# STM32H757xx_CM4 register map
File version: 1.0
Registers are 32-bit, read-write, reset 0x0 unless marked. A register's access mark holds for its fields unless they carry their own. Offsets are from the block's base; [hi:lo] are bit positions; {n}, {i} and the like mark numbered series; 'fields as' and 'values as' point back to an identical list.

## RCC — Reset and Clock Control
Base 0x58024400
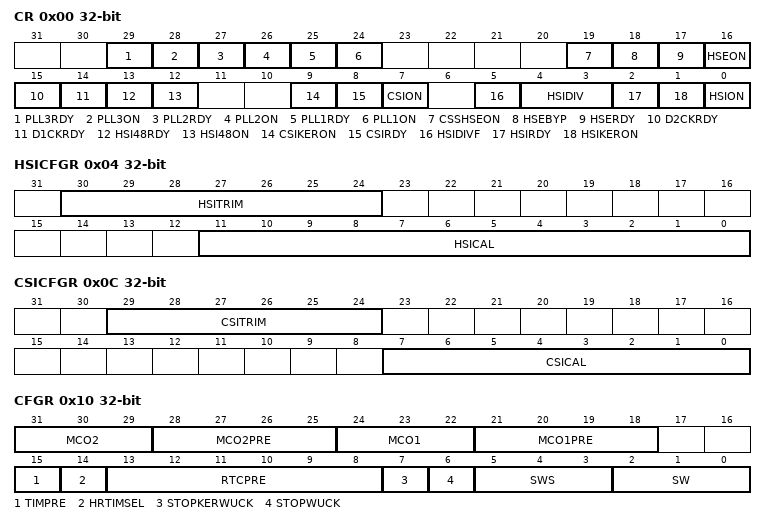
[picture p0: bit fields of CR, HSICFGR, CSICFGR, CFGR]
0x00 CR — RCC clock control register
  [29] PLL3RDY — System PLL3 clock ready
  [28] PLL3ON — System PLL3 clock enable
  [27] PLL2RDY — System PLL2 clock ready
  [26] PLL2ON — System PLL2 clock enable
  [25] PLL1RDY — System PLL1 clock ready
  [24] PLL1ON — System PLL1 clock enable
  [19] CSSHSEON — HSE Clock security System enable
  [18] HSEBYP — External High Speed clock Bypass
  [17] HSERDY — External High Speed clock ready
  [16] HSEON — External High Speed clock enable
  [15] D2CKRDY — D2 domain clocks ready flag
  [14] D1CKRDY — D1 domain clocks ready flag
  [13] HSI48RDY — HSI48 clock ready
  [12] HSI48ON — HSI48 clock enable clock enable
  [9] CSIKERON — Internal RC 4MHz oscillator clock enable for some IPs Kernel
  [8] CSIRDY — The Internal RC 4MHz oscillator clock ready
  [7] CSION — The Internal RC 4MHz oscillator clock enable
  [5] HSIDIVF — HSI Divider flag
  [4:3] HSIDIV — Internal High Speed clock divider selection
    0=DIV1; 1=DIV2; 2=DIV4; 3=DIV8
  [2] HSIRDY — Internal High Speed clock ready flag
  [1] HSIKERON — Internal High Speed clock enable for some IPs Kernel
  [0] HSION — Internal High Speed clock enable
0x04 HSICFGR — HSI Clock Calibration Register
  [30:24] HSITRIM — HSITRIM[6:0] bits
  [11:0] HSICAL — HSICAL[11:0] bits
0x08 CRRCR — Clock Recovery RC Register
  [9:0] HSI48CAL — HSI48CAL[9:0] bits
0x0C CSICFGR — CSI Clock Calibration Register
  [29:24] CSITRIM — CSITRIM[5:0] bits
  [7:0] CSICAL — CSICAL[7:0] bits
0x10 CFGR — RCC clock configuration register
  [31:29] MCO2
  [28:25] MCO2PRE
  [24:22] MCO1
  [21:18] MCO1PRE
  [15] TIMPRE
    0=TWICE; 1=FOUR_TIMES
  [14] HRTIMSEL
    0=TIM; 1=CPU
  [13:8] RTCPRE
    0=NOCLOCK; {v}=HSE_DIV_{v} (v=2..63)
  [7] STOPKERWUCK — Kernel Clock Selection after a Wake Up from STOP
    0=HSI; 1=CSI
  [6] STOPWUCK — Wake Up from stop and CSS backup clock selection
    0=HSI; 1=CSI
  [5:3] SWS — SWS[2:0] bits (System Clock Switch Status)
    0=HSI (HSI used as system clock); 1=CSI (CSI used as system clock); 2=HSE (HSE used as system clock); 3=PLL1 (PLL1 used as system clock)
  [2:0] SW — SW[2:0] bits (System clock Switch)
    0=HSI; 1=CSI; 2=HSE; 3=PLL1
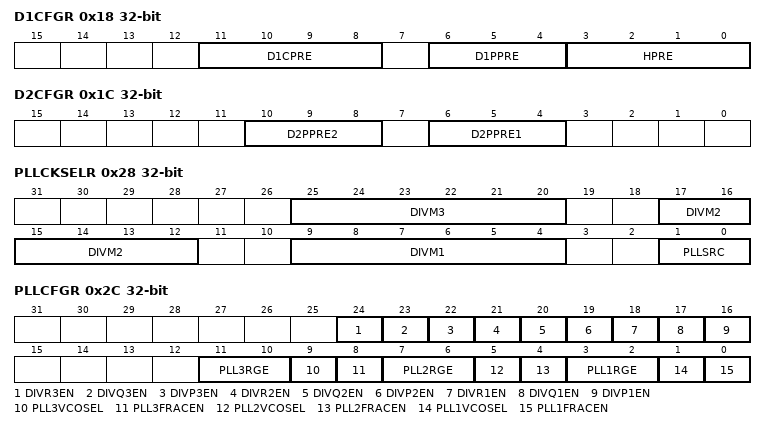
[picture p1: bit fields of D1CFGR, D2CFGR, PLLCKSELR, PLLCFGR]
0x18 D1CFGR — RCC Domain 1 configuration register
  [11:8] D1CPRE — D1CPRE[2:0] bits (Domain 1 Core prescaler)
  [6:4] D1PPRE — D1PRE[2:0] bits (APB3 prescaler)
  [3:0] HPRE — HPRE[3:0] bits (AHB3 prescaler)
0x1C D2CFGR — RCC Domain 2 configuration register
  [10:8] D2PPRE2 — D2PPRE2[2:0] bits (APB2 prescaler)
  [6:4] D2PPRE1 — D1PPRE1[2:0] bits (APB1 prescaler)
0x20 D3CFGR — RCC Domain 3 configuration register
  [6:4] D3PPRE — D3PPRE1[2:0] bits (APB4 prescaler)
0x28 PLLCKSELR — RCC PLLs Clock Source Selection Register
  [25:20] DIVM3
  [17:12] DIVM2
  [9:4] DIVM1
  [1:0] PLLSRC
    0=HSI; 1=CSI; 2=HSE; 3=NONE
0x2C PLLCFGR — RCC PLLs Configuration Register
  [24] DIVR3EN, [23] DIVQ3EN, [22] DIVP3EN, [21] DIVR2EN, [20] DIVQ2EN, [19] DIVP2EN, [18] DIVR1EN, [17] DIVQ1EN, [16] DIVP1EN, [11:10] PLL3RGE, [9] PLL3VCOSEL, [8] PLL3FRACEN, [7:6] PLL2RGE, [5] PLL2VCOSEL, [4] PLL2FRACEN, [3:2] PLL1RGE, [1] PLL1VCOSEL, [0] PLL1FRACEN
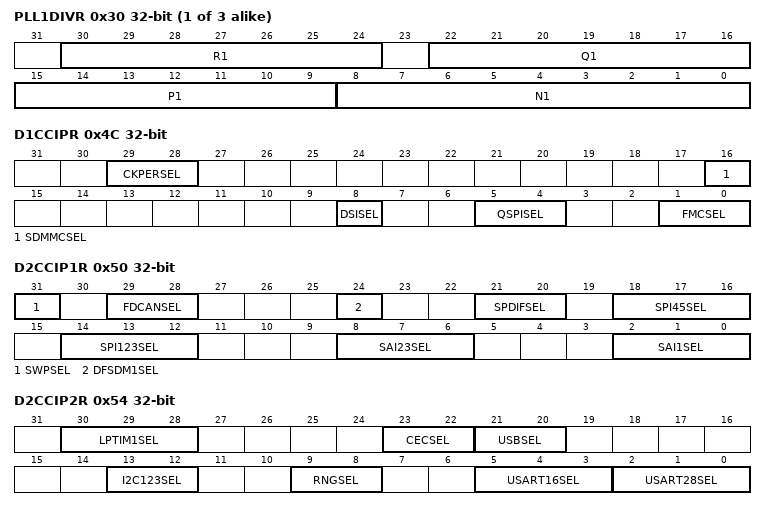
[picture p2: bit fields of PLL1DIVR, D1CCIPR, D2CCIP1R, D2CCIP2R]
{0x28+8i} PLL{i}DIVR (i=1..3) — RCC PLL{i} Dividers Configuration Register
  [30:24] R{i}, [22:16] Q{i}, [15:9] P{i}, [8:0] N{i}
{0x2C+8i} PLL{i}FRACR (i=1..3) — RCC PLL{i} Fractional Divider Configuration Register
  [15:3] FRACN{i}
0x4C D1CCIPR — RCC Domain 1 Kernel Clock Configuration Register
  [29:28] CKPERSEL
  [16] SDMMCSEL
  [8] DSISEL
    0=PHY; 1=PLL2Q
  [5:4] QSPISEL
    0=HCLK; 1=PLL1Q; 2=PLL2R; 3=CLKP
  [1:0] FMCSEL
0x50 D2CCIP1R — RCC Domain 2 Kernel Clock Configuration Register
  [31] SWPSEL, [29:28] FDCANSEL, [24] DFSDM1SEL, [21:20] SPDIFSEL, [18:16] SPI45SEL, [14:12] SPI123SEL, [8:6] SAI23SEL, [2:0] SAI1SEL
0x54 D2CCIP2R — RCC Domain 2 Kernel Clock Configuration Register
  [30:28] LPTIM1SEL, [23:22] CECSEL, [21:20] USBSEL, [13:12] I2C123SEL, [9:8] RNGSEL, [5:3] USART16SEL, [2:0] USART28SEL
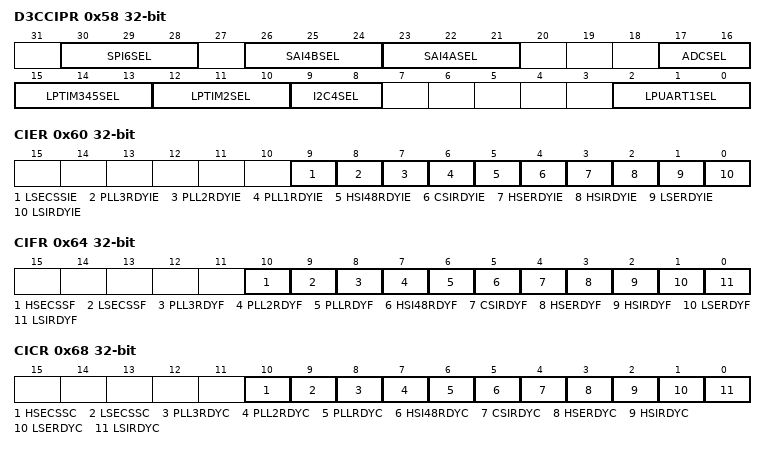
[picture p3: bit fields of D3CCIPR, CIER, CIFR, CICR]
0x58 D3CCIPR — RCC Domain 3 Kernel Clock Configuration Register
  [30:28] SPI6SEL, [26:24] SAI4BSEL, [23:21] SAI4ASEL, [17:16] ADCSEL, [15:13] LPTIM345SEL, [12:10] LPTIM2SEL, [9:8] I2C4SEL, [2:0] LPUART1SEL
0x60 CIER — RCC Clock Source Interrupt Enable Register
  [9] LSECSSIE, [8] PLL3RDYIE, [7] PLL2RDYIE, [6] PLL1RDYIE, [5] HSI48RDYIE, [4] CSIRDYIE, [3] HSERDYIE, [2] HSIRDYIE, [1] LSERDYIE, [0] LSIRDYIE
0x64 CIFR — RCC Clock Source Interrupt Flag Register
  [10] HSECSSF, [9] LSECSSF, [8] PLL3RDYF, [7] PLL2RDYF, [6] PLLRDYF, [5] HSI48RDYF, [4] CSIRDYF, [3] HSERDYF, [2] HSIRDYF, [1] LSERDYF, [0] LSIRDYF
0x68 CICR — RCC Clock Source Interrupt Clear Register
  [10] HSECSSC, [9] LSECSSC, [8] PLL3RDYC, [7] PLL2RDYC, [6] PLLRDYC, [5] HSI48RDYC, [4] CSIRDYC, [3] HSERDYC, [2] HSIRDYC, [1] LSERDYC, [0] LSIRDYC
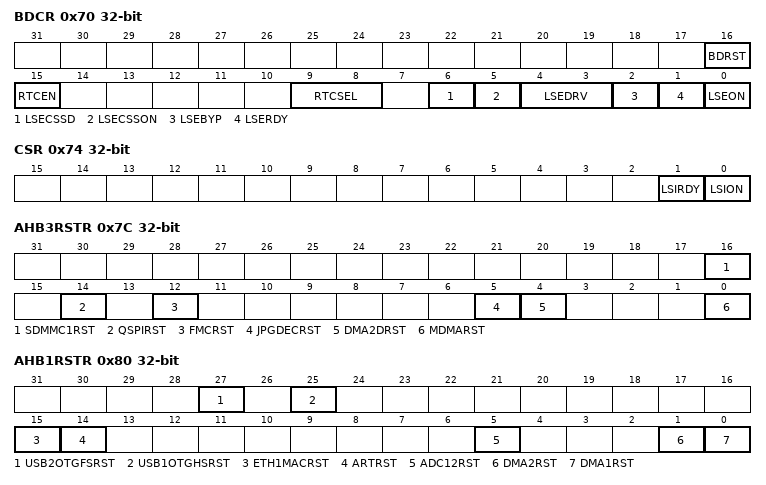
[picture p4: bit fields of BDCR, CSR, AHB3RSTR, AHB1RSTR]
0x70 BDCR — RCC Vswitch Backup Domain Control Register
  [16] BDRST
  [15] RTCEN
  [9:8] RTCSEL
    0=NONE; 1=LSE; 2=LSI; 3=HSE
  [6] LSECSSD
  [5] LSECSSON
  [4:3] LSEDRV
    0=LOW; 1=MEDIUMLOW; 2=MEDIUMHIGH; 3=HIGH
  [2] LSEBYP
  [1] LSERDY
  [0] LSEON
0x74 CSR — RCC clock control & status register
  [1] LSIRDY, [0] LSION
0x7C AHB3RSTR — RCC AHB3 peripheral reset register
  [16] SDMMC1RST, [14] QSPIRST, [12] FMCRST, [5] JPGDECRST, [4] DMA2DRST, [0] MDMARST
0x80 AHB1RSTR — RCC AHB1 peripheral reset register
  [27] USB2OTGFSRST, [25] USB1OTGHSRST, [15] ETH1MACRST, [14] ARTRST, [5] ADC12RST, [1] DMA2RST, [0] DMA1RST
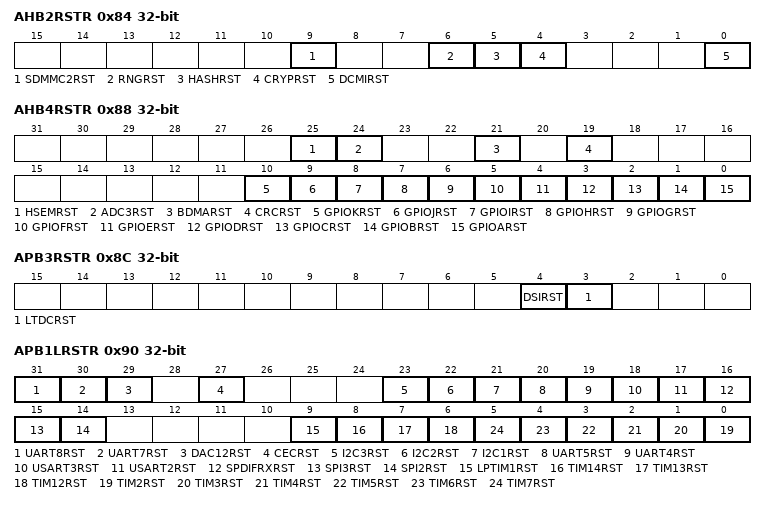
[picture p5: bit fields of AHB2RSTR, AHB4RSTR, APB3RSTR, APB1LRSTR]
0x84 AHB2RSTR — RCC AHB2 peripheral reset register
  [9] SDMMC2RST, [6] RNGRST, [5] HASHRST, [4] CRYPRST, [0] DCMIRST
0x88 AHB4RSTR — RCC AHB4 peripheral reset register
  [25] HSEMRST, [24] ADC3RST, [21] BDMARST, [19] CRCRST, [10] GPIOKRST, [9] GPIOJRST, [8] GPIOIRST, [7] GPIOHRST, [6] GPIOGRST, [5] GPIOFRST, [4] GPIOERST, [3] GPIODRST, [2] GPIOCRST, [1] GPIOBRST, [0] GPIOARST
0x8C APB3RSTR — RCC APB3 peripheral reset register
  [4] DSIRST, [3] LTDCRST
0x90 APB1LRSTR — RCC APB1 peripheral reset Low Word register
  [31] UART8RST, [30] UART7RST, [29] DAC12RST, [27] CECRST, [23] I2C3RST, [22] I2C2RST, [21] I2C1RST, [20] UART5RST, [19] UART4RST, [18] USART3RST, [17] USART2RST, [16] SPDIFRXRST, [15] SPI3RST, [14] SPI2RST, [9] LPTIM1RST, [8] TIM14RST, [7] TIM13RST, [6] TIM12RST, [n-2] TIM{n}RST (n=2..7)
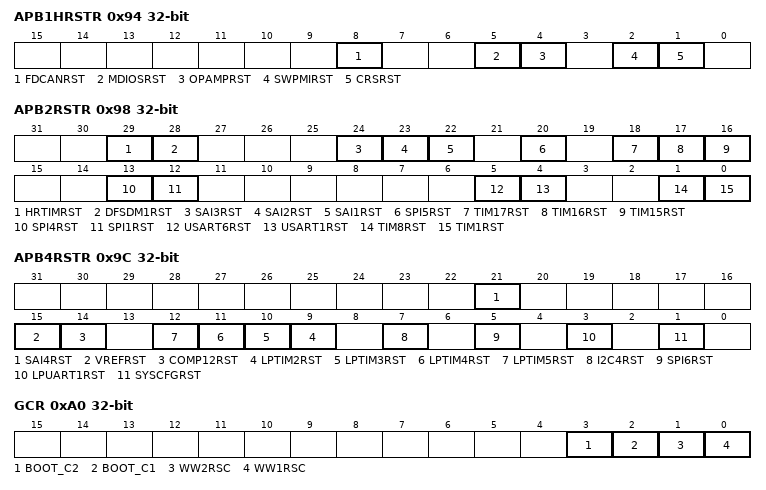
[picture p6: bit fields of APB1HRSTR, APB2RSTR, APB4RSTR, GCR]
0x94 APB1HRSTR — RCC APB1 peripheral reset High Word register
  [8] FDCANRST, [5] MDIOSRST, [4] OPAMPRST, [2] SWPMIRST, [1] CRSRST
0x98 APB2RSTR — RCC APB2 peripheral reset register
  [29] HRTIMRST, [28] DFSDM1RST, [24] SAI3RST, [23] SAI2RST, [22] SAI1RST, [20] SPI5RST, [18] TIM17RST, [17] TIM16RST, [16] TIM15RST, [13] SPI4RST, [12] SPI1RST, [5] USART6RST, [4] USART1RST, [1] TIM8RST, [0] TIM1RST
0x9C APB4RSTR — RCC APB4 peripheral reset register
  [21] SAI4RST, [15] VREFRST, [14] COMP12RST, [n+7] LPTIM{n}RST (n=2..5), [7] I2C4RST, [5] SPI6RST, [3] LPUART1RST, [1] SYSCFGRST
0xA0 GCR — RCC RCC Global Control Register
  [3] BOOT_C2, [2] BOOT_C1, [1] WW2RSC, [0] WW1RSC
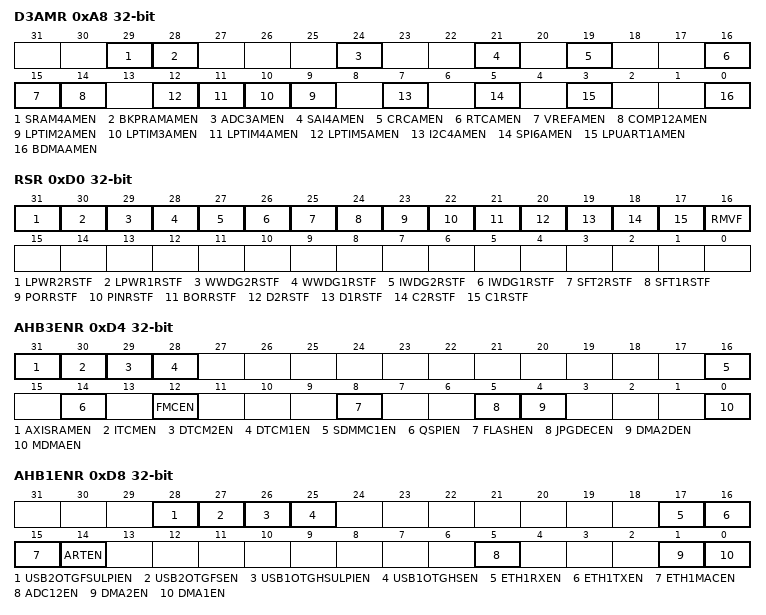
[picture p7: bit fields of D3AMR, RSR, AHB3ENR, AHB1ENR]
0xA8 D3AMR — RCC Domain 3 Autonomous Mode Register
  [29] SRAM4AMEN, [28] BKPRAMAMEN, [24] ADC3AMEN, [21] SAI4AMEN, [19] CRCAMEN, [16] RTCAMEN, [15] VREFAMEN, [14] COMP12AMEN, [n+7] LPTIM{n}AMEN (n=2..5), [7] I2C4AMEN, [5] SPI6AMEN, [3] LPUART1AMEN, [0] BDMAAMEN
0xD0 RSR — RCC Reset status register
  [31] LPWR2RSTF, [30] LPWR1RSTF, [29] WWDG2RSTF, [28] WWDG1RSTF, [27] IWDG2RSTF, [26] IWDG1RSTF, [25] SFT2RSTF, [24] SFT1RSTF, [23] PORRSTF, [22] PINRSTF, [21] BORRSTF, [20] D2RSTF, [19] D1RSTF, [18] C2RSTF, [17] C1RSTF, [16] RMVF
0xD4 AHB3ENR — RCC AHB3 peripheral clock register
  [31] AXISRAMEN, [30] ITCMEN, [29] DTCM2EN, [28] DTCM1EN, [16] SDMMC1EN, [14] QSPIEN, [12] FMCEN, [8] FLASHEN, [5] JPGDECEN, [4] DMA2DEN, [0] MDMAEN
0xD8 AHB1ENR — RCC AHB1 peripheral clock register
  [28] USB2OTGFSULPIEN, [27] USB2OTGFSEN, [26] USB1OTGHSULPIEN, [25] USB1OTGHSEN, [17] ETH1RXEN, [16] ETH1TXEN, [15] ETH1MACEN, [14] ARTEN, [5] ADC12EN, [1] DMA2EN, [0] DMA1EN
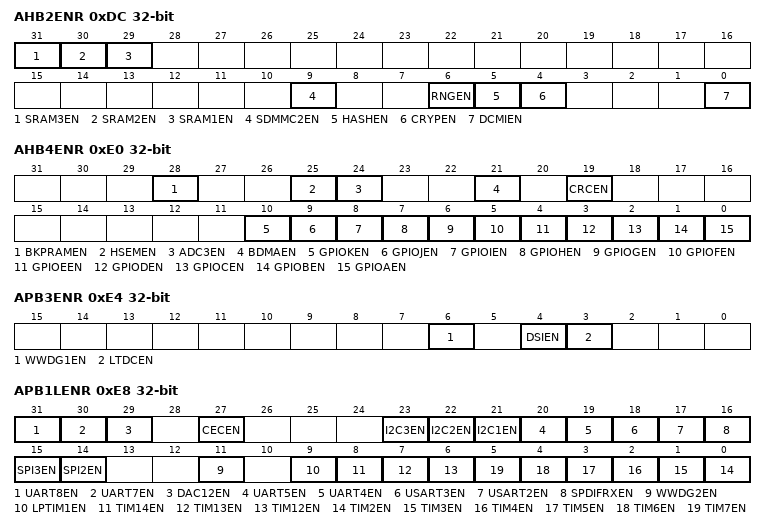
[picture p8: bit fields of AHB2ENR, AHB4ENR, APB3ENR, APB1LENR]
0xDC AHB2ENR — RCC AHB2 peripheral clock register
  [31] SRAM3EN, [30] SRAM2EN, [29] SRAM1EN, [9] SDMMC2EN, [6] RNGEN, [5] HASHEN, [4] CRYPEN, [0] DCMIEN
0xE0 AHB4ENR — RCC AHB4 peripheral clock register
  [28] BKPRAMEN, [25] HSEMEN, [24] ADC3EN, [21] BDMAEN, [19] CRCEN, [10] GPIOKEN, [9] GPIOJEN, [8] GPIOIEN, [7] GPIOHEN, [6] GPIOGEN, [5] GPIOFEN, [4] GPIOEEN, [3] GPIODEN, [2] GPIOCEN, [1] GPIOBEN, [0] GPIOAEN
0xE4 APB3ENR — RCC APB3 peripheral clock register
  [6] WWDG1EN, [4] DSIEN, [3] LTDCEN
0xE8 APB1LENR — RCC APB1 peripheral clock Low Word register
  [31] UART8EN, [30] UART7EN, [29] DAC12EN, [27] CECEN, [23] I2C3EN, [22] I2C2EN, [21] I2C1EN, [20] UART5EN, [19] UART4EN, [18] USART3EN, [17] USART2EN, [16] SPDIFRXEN, [15] SPI3EN, [14] SPI2EN, [11] WWDG2EN, [9] LPTIM1EN, [8] TIM14EN, [7] TIM13EN, [6] TIM12EN, [n-2] TIM{n}EN (n=2..7)
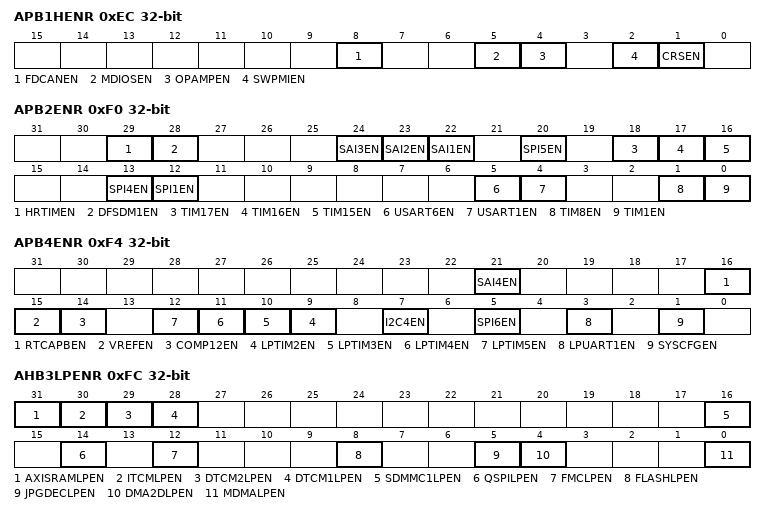
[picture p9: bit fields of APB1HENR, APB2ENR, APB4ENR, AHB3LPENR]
0xEC APB1HENR — RCC APB1 peripheral clock High Word register
  [8] FDCANEN, [5] MDIOSEN, [4] OPAMPEN, [2] SWPMIEN, [1] CRSEN
0xF0 APB2ENR — RCC APB2 peripheral clock register
  [29] HRTIMEN, [28] DFSDM1EN, [24] SAI3EN, [23] SAI2EN, [22] SAI1EN, [20] SPI5EN, [18] TIM17EN, [17] TIM16EN, [16] TIM15EN, [13] SPI4EN, [12] SPI1EN, [5] USART6EN, [4] USART1EN, [1] TIM8EN, [0] TIM1EN
0xF4 APB4ENR — RCC APB4 peripheral clock register
  [21] SAI4EN, [16] RTCAPBEN, [15] VREFEN, [14] COMP12EN, [n+7] LPTIM{n}EN (n=2..5), [7] I2C4EN, [5] SPI6EN, [3] LPUART1EN, [1] SYSCFGEN
0xFC AHB3LPENR — RCC AHB3 peripheral sleep clock register
  [31] AXISRAMLPEN, [30] ITCMLPEN, [29] DTCM2LPEN, [28] DTCM1LPEN, [16] SDMMC1LPEN, [14] QSPILPEN, [12] FMCLPEN, [8] FLASHLPEN, [5] JPGDECLPEN, [4] DMA2DLPEN, [0] MDMALPEN
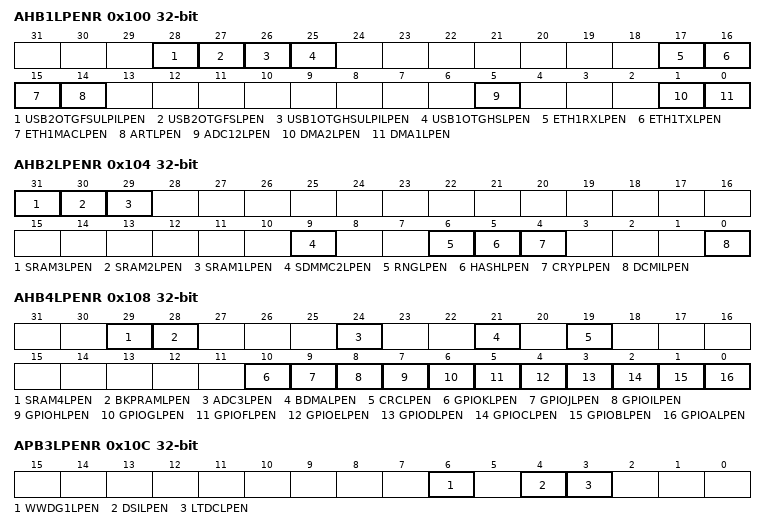
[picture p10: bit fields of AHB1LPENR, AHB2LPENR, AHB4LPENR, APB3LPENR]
0x100 AHB1LPENR — RCC AHB1 peripheral sleep clock register
  [28] USB2OTGFSULPILPEN, [27] USB2OTGFSLPEN, [26] USB1OTGHSULPILPEN, [25] USB1OTGHSLPEN, [17] ETH1RXLPEN, [16] ETH1TXLPEN, [15] ETH1MACLPEN, [14] ARTLPEN, [5] ADC12LPEN, [1] DMA2LPEN, [0] DMA1LPEN
0x104 AHB2LPENR — RCC AHB2 peripheral sleep clock register
  [31] SRAM3LPEN, [30] SRAM2LPEN, [29] SRAM1LPEN, [9] SDMMC2LPEN, [6] RNGLPEN, [5] HASHLPEN, [4] CRYPLPEN, [0] DCMILPEN
0x108 AHB4LPENR — RCC AHB4 peripheral sleep clock register
  [29] SRAM4LPEN, [28] BKPRAMLPEN, [24] ADC3LPEN, [21] BDMALPEN, [19] CRCLPEN, [10] GPIOKLPEN, [9] GPIOJLPEN, [8] GPIOILPEN, [7] GPIOHLPEN, [6] GPIOGLPEN, [5] GPIOFLPEN, [4] GPIOELPEN, [3] GPIODLPEN, [2] GPIOCLPEN, [1] GPIOBLPEN, [0] GPIOALPEN
0x10C APB3LPENR — RCC APB3 peripheral sleep clock register
  [6] WWDG1LPEN, [4] DSILPEN, [3] LTDCLPEN
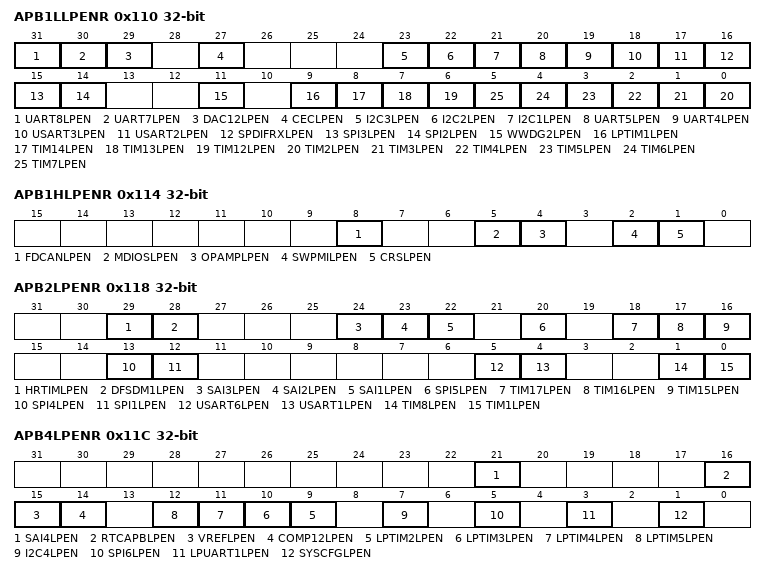
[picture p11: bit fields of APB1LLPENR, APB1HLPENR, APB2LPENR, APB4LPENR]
0x110 APB1LLPENR — RCC APB1 peripheral sleep clock Low Word register
  [31] UART8LPEN, [30] UART7LPEN, [29] DAC12LPEN, [27] CECLPEN, [23] I2C3LPEN, [22] I2C2LPEN, [21] I2C1LPEN, [20] UART5LPEN, [19] UART4LPEN, [18] USART3LPEN, [17] USART2LPEN, [16] SPDIFRXLPEN, [15] SPI3LPEN, [14] SPI2LPEN, [11] WWDG2LPEN, [9] LPTIM1LPEN, [8] TIM14LPEN, [7] TIM13LPEN, [6] TIM12LPEN, [n-2] TIM{n}LPEN (n=2..7)
0x114 APB1HLPENR — RCC APB1 peripheral sleep clock High Word register
  [8] FDCANLPEN, [5] MDIOSLPEN, [4] OPAMPLPEN, [2] SWPMILPEN, [1] CRSLPEN
0x118 APB2LPENR — RCC APB2 peripheral sleep clock register
  [29] HRTIMLPEN, [28] DFSDM1LPEN, [24] SAI3LPEN, [23] SAI2LPEN, [22] SAI1LPEN, [20] SPI5LPEN, [18] TIM17LPEN, [17] TIM16LPEN, [16] TIM15LPEN, [13] SPI4LPEN, [12] SPI1LPEN, [5] USART6LPEN, [4] USART1LPEN, [1] TIM8LPEN, [0] TIM1LPEN
0x11C APB4LPENR — RCC APB4 peripheral sleep clock register
  [21] SAI4LPEN, [16] RTCAPBLPEN, [15] VREFLPEN, [14] COMP12LPEN, [n+7] LPTIM{n}LPEN (n=2..5), [7] I2C4LPEN, [5] SPI6LPEN, [3] LPUART1LPEN, [1] SYSCFGLPEN
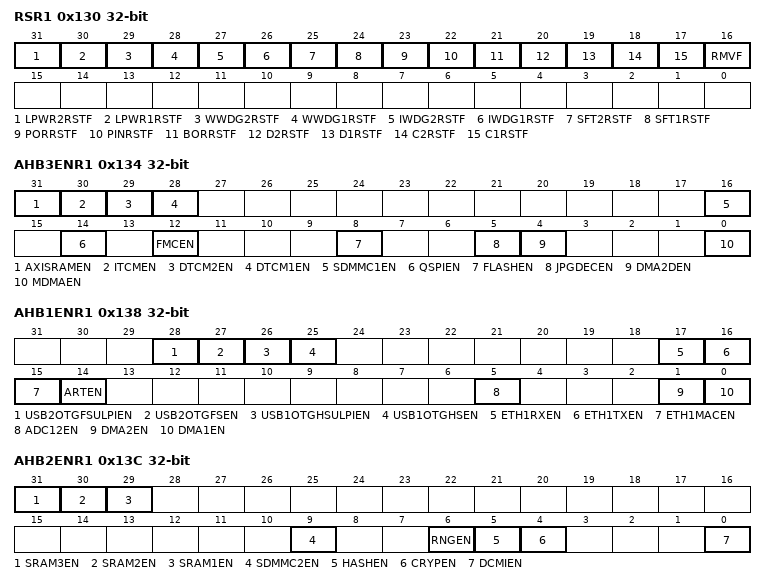
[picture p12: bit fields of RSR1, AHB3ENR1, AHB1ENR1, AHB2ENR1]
0x130 RSR1 — RCC Reset status register
  fields as RSR
0x134 AHB3ENR1 — RCC AHB3 peripheral clock register
  fields as AHB3ENR
0x138 AHB1ENR1 — RCC AHB1 peripheral clock register
  fields as AHB1ENR
0x13C AHB2ENR1 — RCC AHB2 peripheral clock register
  fields as AHB2ENR
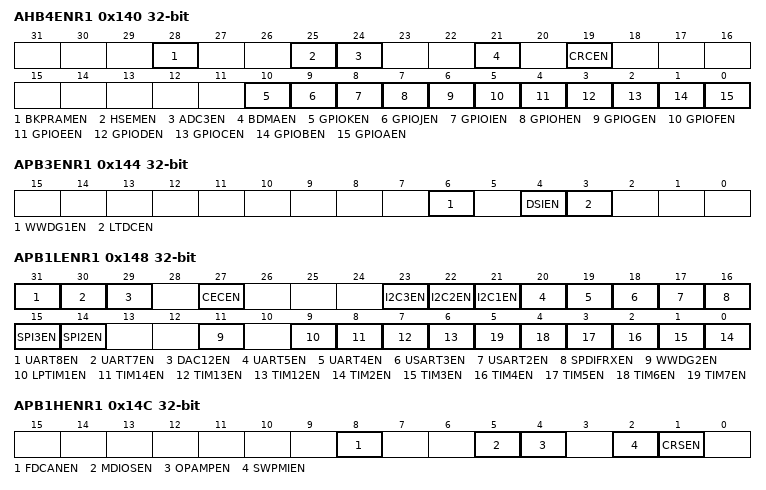
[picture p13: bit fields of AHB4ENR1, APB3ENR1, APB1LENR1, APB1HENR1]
0x140 AHB4ENR1 — RCC AHB4 peripheral clock register
  fields as AHB4ENR
0x144 APB3ENR1 — RCC APB3 peripheral clock register
  [6] WWDG1EN, [4] DSIEN, [3] LTDCEN
0x148 APB1LENR1 — RCC APB1 peripheral clock Low Word register
  fields as APB1LENR
0x14C APB1HENR1 — RCC APB1 peripheral clock High Word register
  [8] FDCANEN, [5] MDIOSEN, [4] OPAMPEN, [2] SWPMIEN, [1] CRSEN
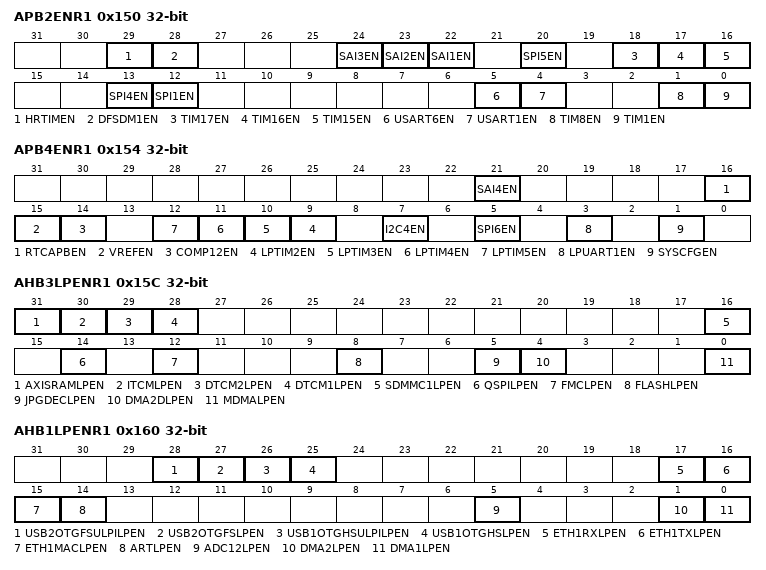
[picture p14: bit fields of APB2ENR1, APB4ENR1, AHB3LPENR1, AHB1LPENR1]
0x150 APB2ENR1 — RCC APB2 peripheral clock register
  fields as APB2ENR
0x154 APB4ENR1 — RCC APB4 peripheral clock register
  fields as APB4ENR
0x15C AHB3LPENR1 — RCC AHB3 peripheral sleep clock register
  fields as AHB3LPENR
0x160 AHB1LPENR1 — RCC AHB1 peripheral sleep clock register
  fields as AHB1LPENR
0x164 AHB2LPENR1 — RCC AHB2 peripheral sleep clock register
  fields as AHB2LPENR
0x168 AHB4LPENR1 — RCC AHB4 peripheral sleep clock register
  fields as AHB4LPENR
0x16C APB3LPENR1 — RCC APB3 peripheral sleep clock register
  [6] WWDG1LPEN, [4] DSILPEN, [3] LTDCLPEN
0x170 APB1LLPENR1 — RCC APB1 peripheral sleep clock Low Word register
  fields as APB1LLPENR
0x174 APB1HLPENR1 — RCC APB1 peripheral sleep clock High Word register
  fields as APB1HLPENR
0x178 APB2LPENR1 — RCC APB2 peripheral sleep clock register
  fields as APB2LPENR
0x17C APB4LPENR1 — RCC APB4 peripheral sleep clock register
  fields as APB4LPENR
0x190 RSR2 — RCC Reset status register
  fields as RSR
0x194 AHB3ENR2 — RCC AHB3 peripheral clock register
  fields as AHB3ENR
0x198 AHB1ENR2 — RCC AHB1 peripheral clock register
  fields as AHB1ENR
0x19C AHB2ENR2 — RCC AHB2 peripheral clock register
  fields as AHB2ENR
0x1A0 AHB4ENR2 — RCC AHB4 peripheral clock register
  fields as AHB4ENR
0x1A4 APB3ENR2 — RCC APB3 peripheral clock register
  [6] WWDG1EN, [4] DSIEN, [3] LTDCEN
0x1A8 APB1LENR2 — RCC APB1 peripheral clock Low Word register
  fields as APB1LENR
0x1AC APB1HENR2 — RCC APB1 peripheral clock High Word register
  [8] FDCANEN, [5] MDIOSEN, [4] OPAMPEN, [2] SWPMIEN, [1] CRSEN
0x1B0 APB2ENR2 — RCC APB2 peripheral clock register
  fields as APB2ENR
0x1B4 APB4ENR2 — RCC APB4 peripheral clock register
  fields as APB4ENR
0x1BC AHB3LPENR2 — RCC AHB3 peripheral sleep clock register
  fields as AHB3LPENR
0x1C0 AHB1LPENR2 — RCC AHB1 peripheral sleep clock register
  fields as AHB1LPENR
0x1C4 AHB2LPENR2 — RCC AHB2 peripheral sleep clock register
  fields as AHB2LPENR
0x1C8 AHB4LPENR2 — RCC AHB4 peripheral sleep clock register
  fields as AHB4LPENR
0x1CC APB3LPENR2 — RCC APB3 peripheral sleep clock register
  [6] WWDG1LPEN, [4] DSILPEN, [3] LTDCLPEN
0x1D0 APB1LLPENR2 — RCC APB1 peripheral sleep clock Low Word register
  fields as APB1LLPENR
0x1D4 APB1HLPENR2 — RCC APB1 peripheral sleep clock High Word register
  fields as APB1HLPENR
0x1D8 APB2LPENR2 — RCC APB2 peripheral sleep clock register
  fields as APB2LPENR
0x1DC APB4LPENR2 — RCC APB4 peripheral sleep clock register
  fields as APB4LPENR
